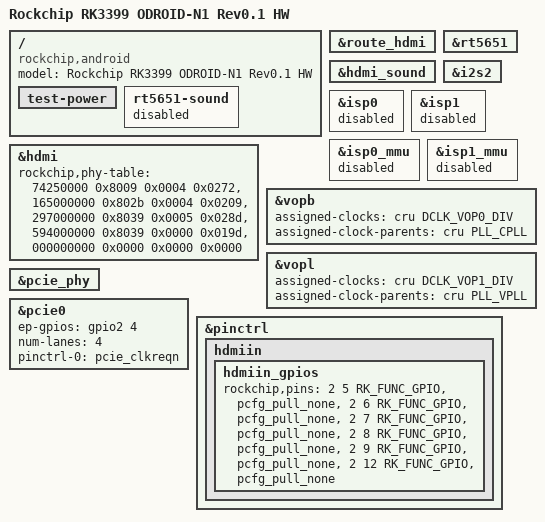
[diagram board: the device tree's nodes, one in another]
/*
 * Copyright (c) 2016 Fuzhou Rockchip Electronics Co., Ltd
 *
 * This file is dual-licensed: you can use it either under the terms
 * of the GPL or the X11 license, at your option. Note that this dual
 * licensing only applies to this file, and not this project as a
 * whole.
 *
 *  a) This file is free software; you can redistribute it and/or
 *     modify it under the terms of the GNU General Public License as
 *     published by the Free Software Foundation; either version 2 of the
 *     License, or (at your option) any later version.
 *
 *     This file is distributed in the hope that it will be useful,
 *     but WITHOUT ANY WARRANTY; without even the implied warranty of
 *     MERCHANTABILITY or FITNESS FOR A PARTICULAR PURPOSE.  See the
 *     GNU General Public License for more details.
 *
 * Or, alternatively,
 *
 *  b) Permission is hereby granted, free of charge, to any person
 *     obtaining a copy of this software and associated documentation
 *     files (the "Software"), to deal in the Software without
 *     restriction, including without limitation the rights to use,
 *     copy, modify, merge, publish, distribute, sublicense, and/or
 *     sell copies of the Software, and to permit persons to whom the
 *     Software is furnished to do so, subject to the following
 *     conditions:
 *
 *     The above copyright notice and this permission notice shall be
 *     included in all copies or substantial portions of the Software.
 *
 *     THE SOFTWARE IS PROVIDED "AS IS", WITHOUT WARRANTY OF ANY KIND,
 *     EXPRESS OR IMPLIED, INCLUDING BUT NOT LIMITED TO THE WARRANTIES
 *     OF MERCHANTABILITY, FITNESS FOR A PARTICULAR PURPOSE AND
 *     NONINFRINGEMENT. IN NO EVENT SHALL THE AUTHORS OR COPYRIGHT
 *     HOLDERS BE LIABLE FOR ANY CLAIM, DAMAGES OR OTHER LIABILITY,
 *     WHETHER IN AN ACTION OF CONTRACT, TORT OR OTHERWISE, ARISING
 *     FROM, OUT OF OR IN CONNECTION WITH THE SOFTWARE OR THE USE OR
 *     OTHER DEALINGS IN THE SOFTWARE.
 */

/dts-v1/;

#include "rk3399-odroidn1.dtsi"
#include "rk3399-android.dtsi"
#include "rk3399-vop-clk-set.dtsi"

/ {
	model = "Rockchip RK3399 ODROID-N1 Rev0.1 HW";
	compatible = "rockchip,android", "rockchip,rk3399-odroidn1-rev0", "rockchip,rk3399";

	test-power {
		status = "okay";
	};

	rt5651-sound {
		status = "disabled";
	};
};

&hdmi {
	status = "okay";
	rockchip,phy-table =
		<74250000 0x8009 0x0004 0x0272>,
		<165000000 0x802b 0x0004 0x0209>,
		<297000000 0x8039 0x0005 0x028d>,
		<594000000 0x8039 0x0000 0x019d>,
		<000000000 0x0000 0x0000 0x0000>;
};

&route_hdmi {
	status = "okay";
};

&rt5651 {
	status = "okay";
};

&hdmi_sound {
	status = "okay";
};

&i2s2 {
	status = "okay";
};

&isp0 {
	status = "disabled";
};

&isp1 {
	status = "disabled";
};

&isp0_mmu {
	status = "disabled";
};

&isp1_mmu {
	status = "disabled";
};

&vopb {
	assigned-clocks = <&cru DCLK_VOP0_DIV>;
	assigned-clock-parents = <&cru PLL_CPLL>;
};

&vopl {
	assigned-clocks = <&cru DCLK_VOP1_DIV>;
	assigned-clock-parents = <&cru PLL_VPLL>;
};

&pcie_phy {
	status = "okay";
};

&pcie0 {
	ep-gpios = <&gpio2 4 GPIO_ACTIVE_HIGH>;
	num-lanes = <4>;
	pinctrl-names = "default";
	pinctrl-0 = <&pcie_clkreqn>;
	status = "okay";
};

&pinctrl {
	hdmiin {
		hdmiin_gpios: hdmiin_gpios {
		rockchip,pins =
				<2 5 RK_FUNC_GPIO &pcfg_pull_none>,
				<2 6 RK_FUNC_GPIO &pcfg_pull_none>,
				<2 7 RK_FUNC_GPIO &pcfg_pull_none>,
				<2 8 RK_FUNC_GPIO &pcfg_pull_none>,
				<2 9 RK_FUNC_GPIO &pcfg_pull_none>,
				<2 12 RK_FUNC_GPIO &pcfg_pull_none>;
		};
	};
};

